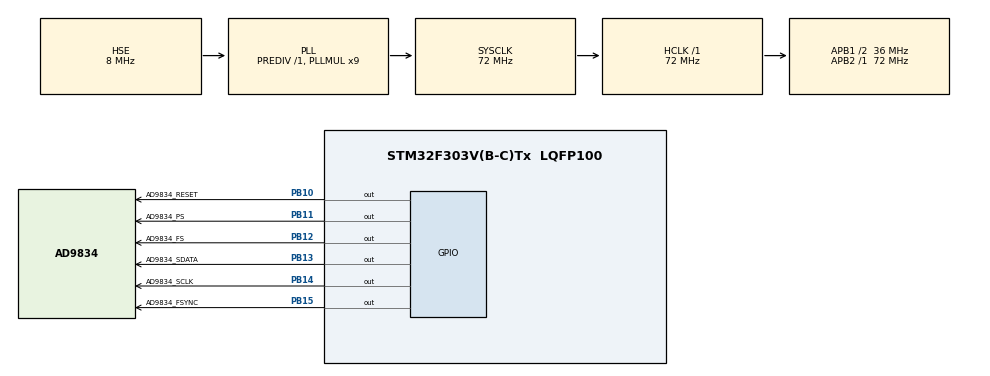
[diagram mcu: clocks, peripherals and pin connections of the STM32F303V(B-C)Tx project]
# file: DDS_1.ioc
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Mcu.Family=STM32F3
Mcu.Name=STM32F303V(B-C)Tx
Mcu.Package=LQFP100
NVIC.PriorityGroup=NVIC_PRIORITYGROUP_4
PA13.Mode=Serial_Wire
PA13.Signal=SYS_JTMS-SWDIO
PA14.Mode=Serial_Wire
PA14.Signal=SYS_JTCK-SWCLK
PB10.GPIO_Label=AD9834_RESET
PB10.Signal=GPIO_Output
PB11.GPIO_Label=AD9834_PS
PB11.Signal=GPIO_Output
PB12.GPIO_Label=AD9834_FS
PB12.Signal=GPIO_Output
PB13.GPIO_Label=AD9834_SDATA
PB13.Signal=GPIO_Output
PB14.GPIO_Label=AD9834_SCLK
PB14.Signal=GPIO_Output
PB15.GPIO_Label=AD9834_FSYNC
PB15.PinState=GPIO_PIN_SET
PB15.Signal=GPIO_Output
PC14-OSC32_IN.Mode=LSE-External-Clock-Source
PC14-OSC32_IN.Signal=RCC_OSC32_IN
PF0-OSC_IN.Mode=HSE-External-Clock-Source
PF0-OSC_IN.Signal=RCC_OSC_IN
ProjectManager.HeapSize=0x200
ProjectManager.StackSize=0x400
ProjectManager.TargetToolchain=STM32CubeIDE
RCC.AHBFreq_Value=72000000
RCC.APB1CLKDivider=RCC_HCLK_DIV2
RCC.APB1Freq_Value=36000000
RCC.APB1TimFreq_Value=72000000
RCC.APB2Freq_Value=72000000
RCC.APB2TimFreq_Value=72000000
RCC.CortexFreq_Value=72000000
RCC.HCLKFreq_Value=72000000
RCC.HSE_VALUE=8000000
RCC.HSI_VALUE=8000000
RCC.LSE_VALUE=32768
RCC.PLLMUL=RCC_PLL_MUL9
RCC.PLLSourceVirtual=RCC_PLLSOURCE_HSE
RCC.SYSCLKFreq_VALUE=72000000
RCC.SYSCLKSourceVirtual=RCC_SYSCLKSOURCE_PLLCLK
RCC.USBFreq_Value=72000000
board=custom

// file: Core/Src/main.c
/* USER CODE BEGIN Header */
/**
  ******************************************************************************
  * @file           : main.c
  * @brief          : Main program body
  ******************************************************************************
  * @attention
  *
  * Copyright (c) 2023 STMicroelectronics.
  * All rights reserved.
  *
  * This software is licensed under terms that can be found in the LICENSE file
  * in the root directory of this software component.
  * If no LICENSE file comes with this software, it is provided AS-IS.
  *
  ******************************************************************************
  */
/* USER CODE END Header */
#include "main.h"

/* USER CODE BEGIN Includes */
#include "AD9834.h"
/* USER CODE END Includes */

void SystemClock_Config(void);
static void MX_GPIO_Init(void);

int main(void)
{

  /* MCU Configuration--------------------------------------------------------*/

  /* Reset of all peripherals, Initializes the Flash interface and the Systick. */
  HAL_Init();

  /* Configure the system clock */
  SystemClock_Config();

  /* Initialize all configured peripherals */
  MX_GPIO_Init();
  /* USER CODE BEGIN 2 */
    HAL_Delay(1000); //等待电平恢复稳定
    AD9834_Init();
    AD9834_Select_Wave(Sine_Wave);//Sine_Wave Square_Wave Triangle_Wave
    AD9834_Set_Freq(FREQ_0, 10000);
    //后续直接选波即可，这里使用的是频率寄存器0
    //后续直接选波即可，这里使用的是频率寄存器0

  /* USER CODE END 2 */

  /* Infinite loop */
  while (1)
  {

  }
}

void SystemClock_Config(void)
{
  RCC_OscInitTypeDef RCC_OscInitStruct = {0};
  RCC_ClkInitTypeDef RCC_ClkInitStruct = {0};

  /** Initializes the RCC Oscillators according to the specified parameters
  * in the RCC_OscInitTypeDef structure.
  */
  RCC_OscInitStruct.OscillatorType = RCC_OSCILLATORTYPE_HSE;
  RCC_OscInitStruct.HSEState = RCC_HSE_BYPASS;
  RCC_OscInitStruct.HSEPredivValue = RCC_HSE_PREDIV_DIV1;
  RCC_OscInitStruct.HSIState = RCC_HSI_ON;
  RCC_OscInitStruct.PLL.PLLState = RCC_PLL_ON;
  RCC_OscInitStruct.PLL.PLLSource = RCC_PLLSOURCE_HSE;
  RCC_OscInitStruct.PLL.PLLMUL = RCC_PLL_MUL9;
  if (HAL_RCC_OscConfig(&RCC_OscInitStruct) != HAL_OK)
  {
    Error_Handler();
  }

  /** Initializes the CPU, AHB and APB buses clocks
  */
  RCC_ClkInitStruct.ClockType = RCC_CLOCKTYPE_HCLK|RCC_CLOCKTYPE_SYSCLK
                              |RCC_CLOCKTYPE_PCLK1|RCC_CLOCKTYPE_PCLK2;
  RCC_ClkInitStruct.SYSCLKSource = RCC_SYSCLKSOURCE_PLLCLK;
  RCC_ClkInitStruct.AHBCLKDivider = RCC_SYSCLK_DIV1;
  RCC_ClkInitStruct.APB1CLKDivider = RCC_HCLK_DIV2;
  RCC_ClkInitStruct.APB2CLKDivider = RCC_HCLK_DIV1;

  if (HAL_RCC_ClockConfig(&RCC_ClkInitStruct, FLASH_LATENCY_2) != HAL_OK)
  {
    Error_Handler();
  }
}

static void MX_GPIO_Init(void)
{
  GPIO_InitTypeDef GPIO_InitStruct = {0};

  /* GPIO Ports Clock Enable */
  __HAL_RCC_GPIOC_CLK_ENABLE();
  __HAL_RCC_GPIOF_CLK_ENABLE();
  __HAL_RCC_GPIOB_CLK_ENABLE();
  __HAL_RCC_GPIOA_CLK_ENABLE();

  /*Configure GPIO pin Output Level */
  HAL_GPIO_WritePin(GPIOB, AD9834_RESET_Pin|AD9834_PS_Pin|AD9834_FS_Pin|AD9834_SDATA_Pin
                          |AD9834_SCLK_Pin, GPIO_PIN_RESET);

  /*Configure GPIO pin Output Level */
  HAL_GPIO_WritePin(AD9834_FSYNC_GPIO_Port, AD9834_FSYNC_Pin, GPIO_PIN_SET);

  /*Configure GPIO pins : AD9834_RESET_Pin AD9834_PS_Pin AD9834_FS_Pin AD9834_SDATA_Pin
                           AD9834_SCLK_Pin AD9834_FSYNC_Pin */
  GPIO_InitStruct.Pin = AD9834_RESET_Pin|AD9834_PS_Pin|AD9834_FS_Pin|AD9834_SDATA_Pin
                          |AD9834_SCLK_Pin|AD9834_FSYNC_Pin;
  GPIO_InitStruct.Mode = GPIO_MODE_OUTPUT_PP;
  GPIO_InitStruct.Pull = GPIO_NOPULL;
  GPIO_InitStruct.Speed = GPIO_SPEED_FREQ_LOW;
  HAL_GPIO_Init(GPIOB, &GPIO_InitStruct);

}

void Error_Handler(void)
{
  __disable_irq();
  while (1)
  {
  }
}
